# f29h85x_fri_ctrl_regs register map
Vendor: Texas Instruments
Peripheral module from a debugger description file (folder HSM).
Registers are 32-bit, read-write, no defined reset value unless marked. A register's access mark holds for its fields unless they carry their own. Offsets are as the file gives them; lines under a group give offsets from that group; [hi:lo] are bit positions; {n}, {i} and the like mark numbered series; 'fields as' and 'values as' point back to an identical list; <NAME> marks a mode.

## FRI_CTRL_REGS — FRI CTRL Registers
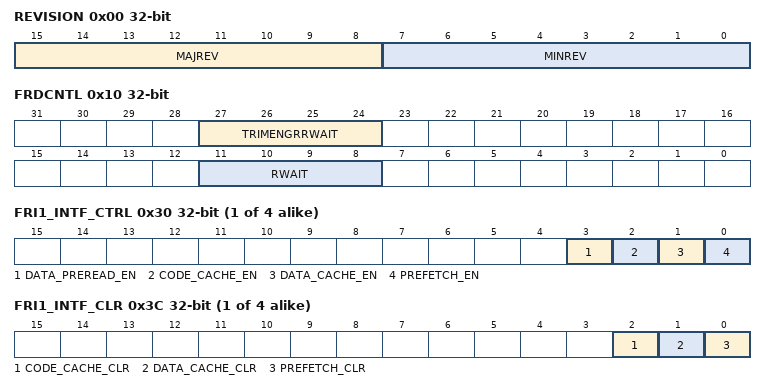
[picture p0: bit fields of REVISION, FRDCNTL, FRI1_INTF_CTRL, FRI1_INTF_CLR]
0x00 REVISION ro — IP Revision Register
  [15:8] MAJREV — Major Revision Number
  [7:0] MINREV — Minor Revision Number
0x10 FRDCNTL — Flash Read Control Register
  [27:24] TRIMENGRRWAIT — Read Waitstate of Trim and ENGR sectors
  [11:8] RWAIT — Read Waitstate
0x14 FRDCNTL_LOCK — Flash Read Control Lock Register
  [0] LOCK
0x18 FRDCNTL_COMMIT — Flash Read Control Commit Register
  [0] COMMIT — FRDCNTL_LOCK Permanent Commit
{0x20+0x10*i} FRI{i}_INTF_CTRL (i=1..4) — Flash Read Interface {i} Control Register
  [3] DATA_PREREAD_EN — Sequential Data Preread Mode Enable
  [2] CODE_CACHE_EN — Code Cache Enable
  [1] DATA_CACHE_EN — Data Line Buffer Enable
  [0] PREFETCH_EN — Prefetch Enable
{0x24+0x10*i} FRI{i}_INTF_CTRL_LOCK (i=1..4) — Flash Read Interface {i} Control Lock Register
  [0] LOCK
{0x28+0x10*i} FRI{i}_INTF_CTRL_COMMIT (i=1..4) — Flash Read Interface {i} Control Commit Register
  [0] COMMIT — FRD_INTF_CTRL_LOCK Permanent Commit
{0x2C+0x10*i} FRI{i}_INTF_CLR (i=1..4) — Flash Read Interface {i} Clear Register
  [2] CODE_CACHE_CLR — Code Cache Clear
  [1] DATA_CACHE_CLR — Data Line Buffer Clear
  [0] PREFETCH_CLR — Prefetch Clear
0x70 PARITY_TEST — Parity Test Enable
  [3:0] TESTEN
0x74 PARITY_TEST_LOCK
  [0] LOCK
0x78 PARITY_TEST_COMMIT
  [0] COMMIT — PARITY_TEST_LOCK Permanent Commit
